# ISS_ISP5_SYS1 register map
Vendor: Texas Instruments
Registers are 32-bit, access not given, reset 0x0 unless marked. A register's access mark holds for its fields unless they carry their own. Offsets are as the file gives them; [hi:lo] are bit positions; {n}, {i} and the like mark numbered series.

## ISS_ISP5_SYS1 (part 2 of 2)
0x00 ISP5_REVISION ro reset not defined — IP Revision Identifier (X.Y.R) Used by software to track features, bugs, and compatibility
  [31:0] REVISION — IP Revision
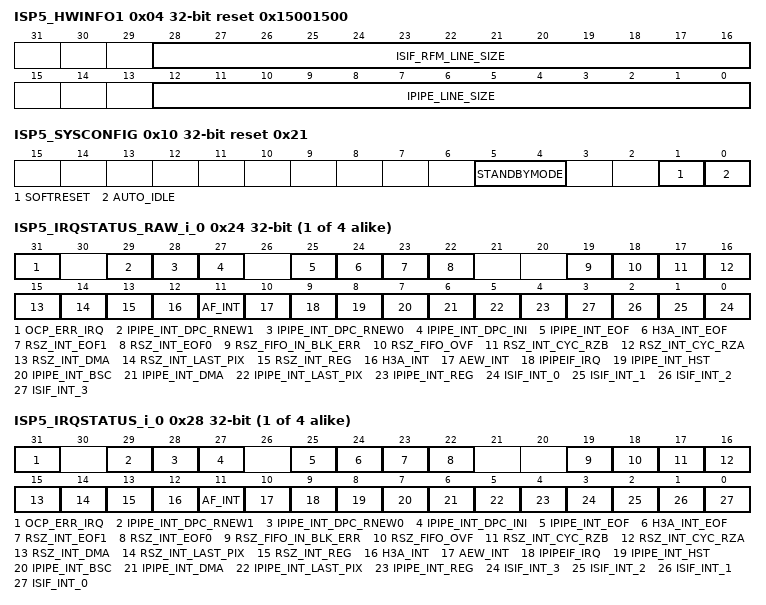
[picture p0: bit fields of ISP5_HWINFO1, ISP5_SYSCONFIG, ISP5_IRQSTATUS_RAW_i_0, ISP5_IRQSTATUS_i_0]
0x04 ISP5_HWINFO1 ro reset 0x15001500 — GENERIC PARAMETER REGISTER Information about the hardware configuration of the IP module.
  [28:16] ISIF_RFM_LINE_SIZE — Memory line size for the data reformatter in the ISIF module.
  [12:0] IPIPE_LINE_SIZE — Memory line size for the IPIPE module
0x08 ISP5_HWINFO2 ro reset 0xBC0 — GENERIC PARAMETER REGISTER Information about the hardware configuration of the IP module.
  [12:0] H3A_LINE_SIZE — Memory line size for the H3A module
0x10 ISP5_SYSCONFIG access per field reset 0x21 — Clock management configuration
  [5:4] STANDBYMODE rw — Configuration of the local initiator state management mode. By definition, initiator may generate read/write transaction as long as it is out of STANDBY state.
    0=Force-standby mode: local initiator is unconditionally placed in standby state. Backup mode, for debug only.; 1=No-standby mode: local initiator is unconditionally placed out of standby state. Backup mode, for debug only.; 2=Smart-standby mode: local initiator standby status depends on local conditions, that is, the module's functional requirement from the initiator. IP module must not generate (initiator-related) wake-up events. Generation of the MStandby signal must be initiated by the firmware by writing .MSTANDBY = 1.
  [1] SOFTRESET rw — Software reset. The soft reset will cause the MStandby to be asserted as the reset value of the ISP5_CTRL.MSTANDBY bit is 1. After a soft reset, the software must ensure not to perform any access for 16 clock cycles (OCP-slave port frequency) after writing this bit. The OCP slave port is running at half the frequency of the functional clock. Before issuing a soft reset, the software must ensure that no more traffic is being generated by the ISP. Basically, it means that the camera module must be stopped from sending data and/or that the ISP modules are disabled. The last interrupt triggered by the ISP design upon completion of the frame processing is rsz_int_dma. This rsz_int_dma event must be used to enable clean termination of the processing. The software must wait a few hundred cycles to trigger the soft reset after upon assertion of the rsz_int_dma, this is to ensure that the BL is completely drained. Software must set the ISP in standby mode before issuing the soft reset: Set ISP5_SYSCONFIG.STANDBYMODE = 2 (smart standby). Set ISP5_CTRL.MSTANDBY to 1. Poll for ISP5_CTRL.MSTANDBY_WAIT = 1. Then, the soft reset can be applied (ISP5_SYSCONFIG.SOFTRESET = 1).
    0=SOFTRESET_0_w (No action); 1=SOFTRESET_1_w (Initiate software reset); 1=SOFTRESET_1_r (Reset (software or other) ongoing); 0=SOFTRESET_0_r (Reset done, no pending action)
  [0] AUTO_IDLE ro — Auto clock gating. Always enabled.
{0x24+0x10*i} ISP5_IRQSTATUS_RAW_i_{i} (i=0..3) — Per-event raw interrupt status vector. Raw status is set even if event is not enabled. Write 1 to set the (raw) status, mostly for debug. The ISP outputs four interrupt lines, ISP_IRQ0 to ISP_IRQ3. Any internal ISP event can be merged on the four lines. A same event must be enabled on only one interrupt line.
  [31] OCP_ERR_IRQ — An OCP error has been received on the ISP master port. (access RW W1toSet)
    0=OCP_ERR_IRQ_0_w (No action); 1=OCP_ERR_IRQ_1_w (Set event (debug)); 1=OCP_ERR_IRQ_1_r (Event pending); 0=OCP_ERR_IRQ_0_r (No event pending)
  [29] IPIPE_INT_DPC_RNEW1 — (access RW W1toSet)
    0=IPIPE_INT_DPC_RNEW1_0_w (No action); 1=IPIPE_INT_DPC_RNEW1_1_w (Set event (debug)); 1=IPIPE_INT_DPC_RNEW1_1_r (Event pending); 0=IPIPE_INT_DPC_RNEW1_0_r (No event pending)
  [28] IPIPE_INT_DPC_RNEW0 — (access RW W1toSet)
    0=IPIPE_INT_DPC_RNEW0_0_w (No action); 1=IPIPE_INT_DPC_RNEW0_1_w (Set event (debug)); 1=IPIPE_INT_DPC_RNEW0_1_r (Event pending); 0=IPIPE_INT_DPC_RNEW0_0_r (No event pending)
  [27] IPIPE_INT_DPC_INI — (access RW W1toSet)
    0=IPIPE_INT_DPC_INI_0_w (No action); 1=IPIPE_INT_DPC_INI_1_w (Set event (debug)); 1=IPIPE_INT_DPC_INI_1_r (Event pending); 0=IPIPE_INT_DPC_INI_0_r (No event pending)
  [25] IPIPE_INT_EOF — (access RW W1toSet)
    0=IPIPE_INT_EOF_0_w (No action); 1=IPIPE_INT_EOF_1_w (Set event (debug)); 1=IPIPE_INT_EOF_1_r (Event pending); 0=IPIPE_INT_EOF_0_r (No event pending)
  [24] H3A_INT_EOF — (access RW W1toSet)
    0=H3A_INT_EOF_0_w (No action); 1=H3A_INT_EOF_1_w (Set event (debug)); 1=H3A_INT_EOF_1_r (Event pending); 0=H3A_INT_EOF_0_r (No event pending)
  [23] RSZ_INT_EOF1 — RESIZER module event: This event signals that the BL has received the EOF signal from the resizer B engine which happens one the last transfer in the frame has happened. Note that because the BL has FIFOs it may take some additional time before true data transfer completion to memory. (access RW W1toSet)
    0=RSZ_INT_EOF1_0_w (No action); 1=RSZ_INT_EOF1_1_w (Set event (debug)); 1=RSZ_INT_EOF1_1_r (Event pending); 0=RSZ_INT_EOF1_0_r (No event pending)
  [22] RSZ_INT_EOF0 — RESIZER module event: This event signals that the BL has received the EOF signal from the resizer A engine which happens one the last transfer in the frame has happened. Note that because the BL has FIFOs it may take some additional time before true data transfer completion to memory. (access RW W1toSet)
    0=RSZ_INT_EOF0_0_w (No action); 1=RSZ_INT_EOF0_1_w (Set event (debug)); 1=RSZ_INT_EOF0_1_r (Event pending); 0=RSZ_INT_EOF0_0_r (No event pending)
  [19] RSZ_FIFO_IN_BLK_ERR — This event signals that the minimum vertical blanking period has not been respected causing errors in the input data buffering submodule. This event will be triggered when the rsz_int_reg event of frame N is triggered before the rsz_int_dma of frame N + 1. This event would typically happen at the transition between two frames because there is not enough vertical blanking between frames: the firmware must take care to ensure enough vertical blanking. The hardware cannot recover from this error. It will be required to perform a reset of the IP. (access RW W1toSet)
    0=RSZ_FIFO_IN_BLK_ERR_0_w (No action); 1=RSZ_FIFO_IN_BLK_ERR_1_w (Set event (debug)); 1=RSZ_FIFO_IN_BLK_ERR_1_r (Event pending); 0=RSZ_FIFO_IN_BLK_ERR_0_r (No event pending)
  [18] RSZ_FIFO_OVF — This event signals that overflow happened in the input data buffering submodule. This event would typically happen while processing a frame because the video port pixel clock is too high: the firmware must take care to use a lower pixel clock at the input of the resizer module. Depending on the mode being used, the overflow can happen at different places: 1. Bypass mode: overflow happened in the input circular buffer. 2. Pass through mode: overflow happened on the module output interface (MTC) 3. Normal resize mode: overflow happened in the input circular buffer. The hardware cannot recover from this error. It will be required to perform a reset of the IP. (access RW W1toSet)
    0=RSZ_FIFO_OVF_0_w (No action); 1=RSZ_FIFO_OVF_1_w (Set event (debug)); 1=RSZ_FIFO_OVF_1_r (Event pending); 0=RSZ_FIFO_OVF_0_r (No event pending)
  [17] RSZ_INT_CYC_RZB — RESIZER module event: This event is the circular interrupt for RESIZER #B. An event can be triggered every time that RSZ_IRQ_RZB output lines have been written out to the RZB_SDR_Y buffer. The range can go from 1 to 8192 lines. Usually, this value should be such that the circular buffer vertical size (set by the RZB_SDR_Y_PTR_E register) is a multiple of RSZ_IRQ_RZB. Note that at the time the interrupt is triggered, the actual data write has not taken place. It may take a few hundred of cycles to complete the data write into system memory. This is not an issue since the start of the buffer is read first. (access RW W1toSet)
    0=RSZ_INT_CYC_RZB_0_w (No action); 1=RSZ_INT_CYC_RZB_1_w (Set event (debug)); 1=RSZ_INT_CYC_RZB_1_r (Event pending); 0=RSZ_INT_CYC_RZB_0_r (No event pending)
  [16] RSZ_INT_CYC_RZA — RESIZER module event: This event is the circular interrupt for RESIZER #A. An event can be triggered every time that RSZ_IRQ_RZA output lines have been written out to the RZA_SDR_Y buffer. The range can go from 1 to 8192 lines. Usually, the circular buffer vertical size (set by the RZA_SDR_Y_PTR_E register) should be a multiple of RSZ_IRQ_RZA. Note that at the time the interrupt is triggered, the actual data write has not taken place. It may take a few hundred of cycles to complete the data write into system memory. This is not an issue since the start of the buffer is read first. (access RW W1toSet)
    0=RSZ_INT_CYC_RZA_0_w (No action); 1=RSZ_INT_CYC_RZA_1_w (Set event (debug)); 1=RSZ_INT_CYC_RZA_1_r (Event pending); 0=RSZ_INT_CYC_RZA_0_r (No event pending)
  [15] RSZ_INT_DMA — This event is triggered when the last EOF (of the two MTC interfaces) is sent out to the BL and that the resizer core has returned to idle. rsz_int_dma is a true indication that all processing is finished for the particular frame on both resizer engines. (access RW W1toSet)
    0=RSZ_INT_DMA_0_w (No action); 1=RSZ_INT_DMA_1_w (Set event (debug)); 1=RSZ_INT_DMA_1_r (Event pending); 0=RSZ_INT_DMA_0_r (No event pending)
  [14] RSZ_INT_LAST_PIX — This event is triggered when the last pixel of the valid area is received. (access RW W1toSet)
    0=RSZ_INT_LAST_PIX_0_w (No action); 1=RSZ_INT_LAST_PIX_1_w (Set event (debug)); 1=RSZ_INT_LAST_PIX_1_r (Event pending); 0=RSZ_INT_LAST_PIX_0_r (No event pending)
  [13] RSZ_INT_REG — This event is triggered when the first pixel of the valid area is received. Shadowed registers can be updated at any time but the new value will take effect on the next rsz_int_reg event. (access RW W1toSet)
    0=RSZ_INT_REG_0_w (No action); 1=RSZ_INT_REG_1_w (Set event (debug)); 1=RSZ_INT_REG_1_r (Event pending); 0=RSZ_INT_REG_0_r (No event pending)
  [12] H3A_INT — (access RW W1toSet)
    0=H3A_INT_0_w (No action); 1=H3A_INT_1_w (Set event (debug)); 1=H3A_INT_1_r (Event pending); 0=H3A_INT_0_r (No event pending)
  [11] AF_INT — (access RW W1toSet)
    0=AF_INT_0_w (No action); 1=AF_INT_1_w (Set event (debug)); 1=AF_INT_1_r (Event pending); 0=AF_INT_0_r (No event pending)
  [10] AEW_INT — (access RW W1toSet)
    0=AEW_INT_0_w (No action); 1=AEW_INT_1_w (Set event (debug)); 1=AEW_INT_1_r (Event pending); 0=AEW_INT_0_r (No event pending)
  [9] IPIPEIF_IRQ — IPIPEIF module interrupt (access RW W1toSet)
    0=IPIPEIF_IRQ_0_w (No action); 1=IPIPEIF_IRQ_1_w (Set event (debug)); 1=IPIPEIF_IRQ_1_r (Event pending); 0=IPIPEIF_IRQ_0_r (No event pending)
  [8] IPIPE_INT_HST — (access RW W1toSet)
    0=IPIPE_INT_HST_0_w (No action); 1=IPIPE_INT_HST_1_w (Set event (debug)); 1=IPIPE_INT_HST_1_r (Event pending); 0=IPIPE_INT_HST_0_r (No event pending)
  [7] IPIPE_INT_BSC — (access RW W1toSet)
    0=IPIPE_INT_BSC_0_w (No action); 1=IPIPE_INT_BSC_1_w (Set event (debug)); 1=IPIPE_INT_BSC_1_r (Event pending); 0=IPIPE_INT_BSC_0_r (No event pending)
  [6] IPIPE_INT_DMA — (access RW W1toSet)
    0=IPIPE_INT_DMA_0_w (No action); 1=IPIPE_INT_DMA_1_w (Set event (debug)); 1=IPIPE_INT_DMA_1_r (Event pending); 0=IPIPE_INT_DMA_0_r (No event pending)
  [5] IPIPE_INT_LAST_PIX — (access RW W1toSet)
    0=IPIPE_INT_LAST_PIX_0_w (No action); 1=IPIPE_INT_LAST_PIX_1_w (Set event (debug)); 1=IPIPE_INT_LAST_PIX_1_r (Event pending); 0=IPIPE_INT_LAST_PIX_0_r (No event pending)
  [4] IPIPE_INT_REG — (access RW W1toSet)
    0=IPIPE_INT_REG_0_w (No action); 1=IPIPE_INT_REG_1_w (Set event (debug)); 1=IPIPE_INT_REG_1_r (Event pending); 0=IPIPE_INT_REG_0_r (No event pending)
  [n] ISIF_INT_{n} (n=0..3) — (access RW W1toSet)
    0=ISIF_INT_{n}_0_w (No action); 1=ISIF_INT_{n}_1_w (Set event (debug)); 1=ISIF_INT_{n}_1_r (Event pending); 0=ISIF_INT_{n}_0_r (No event pending)
{0x28+0x10*i} ISP5_IRQSTATUS_i_{i} (i=0..3) — Per-event 'enabled' interrupt status vector. Enabled status is not set unless event is enabled. Write 1 to clear the status after interrupt has been serviced (raw status gets cleared, that is, even if not enabled). The ISP outputs four interrupt lines, ISP_IRQ0 to ISP_IRQ3. Any internal ISP event can be merged on the four lines. A same event must be enabled on only one interrupt line.
  [31] OCP_ERR_IRQ — An OCP error has been received on the ISP master port. (access RW W1toClr)
    0=OCP_ERR_IRQ_0_w (No action); 1=OCP_ERR_IRQ_1_w (Clear (raw) event); 1=OCP_ERR_IRQ_1_r (Event pending); 0=OCP_ERR_IRQ_0_r (No (enabled) event pending)
  [29] IPIPE_INT_DPC_RNEW1 — (access RW W1toClr)
    0=IPIPE_INT_DPC_RNEW1_0_w (No action); 1=IPIPE_INT_DPC_RNEW1_1_w (Clear (raw) event); 1=IPIPE_INT_DPC_RNEW1_1_r (Event pending); 0=IPIPE_INT_DPC_RNEW1_0_r (No (enabled) event pending)
  [28] IPIPE_INT_DPC_RNEW0 — (access RW W1toClr)
    0=IPIPE_INT_DPC_RNEW0_0_w (No action); 1=IPIPE_INT_DPC_RNEW0_1_w (Clear (raw) event); 1=IPIPE_INT_DPC_RNEW0_1_r (Event pending); 0=IPIPE_INT_DPC_RNEW0_0_r (No (enabled) event pending)
  [27] IPIPE_INT_DPC_INI — (access RW W1toClr)
    0=IPIPE_INT_DPC_INI_0_w (No action); 1=IPIPE_INT_DPC_INI_1_w (Clear (raw) event); 1=IPIPE_INT_DPC_INI_1_r (Event pending); 0=IPIPE_INT_DPC_INI_0_r (No (enabled) event pending)
  [25] IPIPE_INT_EOF — (access RW W1toClr)
    0=IPIPE_INT_EOF_0_w (No action); 1=IPIPE_INT_EOF_1_w (Clear (raw) event); 1=IPIPE_INT_EOF_1_r (Event pending); 0=IPIPE_INT_EOF_0_r (No (enabled) event pending)
  [24] H3A_INT_EOF — (access RW W1toClr)
    0=H3A_INT_EOF_0_w (No action); 1=H3A_INT_EOF_1_w (Clear (raw) event); 1=H3A_INT_EOF_1_r (Event pending); 0=H3A_INT_EOF_0_r (No (enabled) event pending)
  [23] RSZ_INT_EOF1 — RESIZER module event: This event signals that the BL has received the EOF signal from the resizer B engine which happens one the last transfer in the frame has happened. Note that because the BL has FIFOs it may take some additional time before true data transfer completion to memory. (access RW W1toClr)
    0=RSZ_INT_EOF1_0_w (No action); 1=RSZ_INT_EOF1_1_w (Clear (raw) event); 1=RSZ_INT_EOF1_1_r (Event pending); 0=RSZ_INT_EOF1_0_r (No (enabled) event pending)
  [22] RSZ_INT_EOF0 — RESIZER module event: This event signals that the BL has received the EOF signal from the resizer A engine which happens one the last transfer in the frame has happened. Note that because the BL has FIFOs it may take some additional time before true data transfer completion to memory. (access RW W1toClr)
    0=RSZ_INT_EOF0_0_w (No action); 1=RSZ_INT_EOF0_1_w (Clear (raw) event); 1=RSZ_INT_EOF0_1_r (Event pending); 0=RSZ_INT_EOF0_0_r (No (enabled) event pending)
  [19] RSZ_FIFO_IN_BLK_ERR — This event signals that the minimum vertical blanking period has not been respected causing errors in the input data buffering submodule. This event will be triggered when the rsz_int_reg event of frame N is triggered before the rsz_int_dma of frame N + 1. This event would typically happen at the transition between two frames because there is not enough vertical blanking between frames: the firmware must take care to ensure enough vertical blanking. The hardware cannot recover from this error. It will be required to perform a reset of the IP. (access RW W1toClr)
    0=RSZ_FIFO_IN_BLK_ERR_0_w (No action); 1=RSZ_FIFO_IN_BLK_ERR_1_w (Clear (raw) event); 1=RSZ_FIFO_IN_BLK_ERR_1_r (Event pending); 0=RSZ_FIFO_IN_BLK_ERR_0_r (No (enabled) event pending)
  [18] RSZ_FIFO_OVF — This event signals that overflow happened in the input data buffering submodule or in the RSZ output interface. This event would typically happen while processing a frame because the video port pixel clock is too high: the firmware must take care to use a lower pixel clock at the input of the resizer module. The hardware cannot recover from this error. It will be required to perform a reset of the IP. (access RW W1toClr)
    0=RSZ_FIFO_OVF_0_w (No action); 1=RSZ_FIFO_OVF_1_w (Clear (raw) event); 1=RSZ_FIFO_OVF_1_r (Event pending); 0=RSZ_FIFO_OVF_0_r (No (enabled) event pending)
  [17] RSZ_INT_CYC_RZB — RESIZER module event: This event is the circular interrupt for RESIZER #B. An event can be triggered every time that RSZ_IRQ_RZB output lines have been written out to the RZB_SDR_Y buffer. The range can go from 1 to 8192 lines. Usually, this value should be such that the circular buffer vertical size (set by the RZB_SDR_Y_PTR_E register) is a multiple of RSZ_IRQ_RZB. Note that at the time the interrupt is triggered, the actual data write has not taken place. It may take a few hundred of cycles to complete the data write into system memory. This is not an issue since the start of the buffer is read first. (access RW W1toClr)
    0=RSZ_INT_CYC_RZB_0_w (No action); 1=RSZ_INT_CYC_RZB_1_w (Clear (raw) event); 1=RSZ_INT_CYC_RZB_1_r (Event pending); 0=RSZ_INT_CYC_RZB_0_r (No (enabled) event pending)
  [16] RSZ_INT_CYC_RZA — RESIZER module event: This event is the circular interrupt for RESIZER #A. An event can be triggered every time that RSZ_IRQ_RZA output lines have been written out to the RZA_SDR_Y buffer. The range can go from 1 to 8192 lines. Usually, the circular buffer vertical size (set by the RZA_SDR_Y_PTR_E register) should be a multiple of RSZ_IRQ_RZA. Note that at the time the interrupt is triggered, the actual data write has not taken place. It may take a few hundred of cycles to complete the data write into system memory. This is not an issue since the start of the buffer is read first. (access RW W1toClr)
    0=RSZ_INT_CYC_RZA_0_w (No action); 1=RSZ_INT_CYC_RZA_1_w (Clear (raw) event); 1=RSZ_INT_CYC_RZA_1_r (Event pending); 0=RSZ_INT_CYC_RZA_0_r (No (enabled) event pending)
  [15] RSZ_INT_DMA — This event is triggered when the last EOF (of the two MTC interfaces) is sent out to the BL and that the resizer core has returned to idle. rsz_int_dma is a true indication that all processing is finished for the particular frame on both resizer engines. (access RW W1toClr)
    0=RSZ_INT_DMA_0_w (No action); 1=RSZ_INT_DMA_1_w (Clear (raw) event); 1=RSZ_INT_DMA_1_r (Event pending); 0=RSZ_INT_DMA_0_r (No (enabled) event pending)
  [14] RSZ_INT_LAST_PIX — This event is triggered when the last pixel of the valid area is received. (access RW W1toClr)
    0=RSZ_INT_LAST_PIX_0_w (No action); 1=RSZ_INT_LAST_PIX_1_w (Clear (raw) event); 1=RSZ_INT_LAST_PIX_1_r (Event pending); 0=RSZ_INT_LAST_PIX_0_r (No (enabled) event pending)
  [13] RSZ_INT_REG — This event is triggered when the first pixel of the valid area is received. Shadowed registers can be updated at any time but the new value will take effect on the next rsz_int_reg event. (access RW W1toClr)
    0=RSZ_INT_REG_0_w (No action); 1=RSZ_INT_REG_1_w (Clear (raw) event); 1=RSZ_INT_REG_1_r (Event pending); 0=RSZ_INT_REG_0_r (No (enabled) event pending)
  [12] H3A_INT — (access RW W1toClr)
    0=H3A_INT_0_w (No action); 1=H3A_INT_1_w (Clear (raw) event); 1=H3A_INT_1_r (Event pending); 0=H3A_INT_0_r (No (enabled) event pending)
  [11] AF_INT — (access RW W1toClr)
    0=AF_INT_0_w (No action); 1=AF_INT_1_w (Clear (raw) event); 1=AF_INT_1_r (Event pending); 0=AF_INT_0_r (No (enabled) event pending)
  [10] AEW_INT — (access RW W1toClr)
    0=AEW_INT_0_w (No action); 1=AEW_INT_1_w (Clear (raw) event); 1=AEW_INT_1_r (Event pending); 0=AEW_INT_0_r (No (enabled) event pending)
  [9] IPIPEIF_IRQ — IPIPEIF module interrupt (access RW W1toClr)
    0=IPIPEIF_IRQ_0_w (No action); 1=IPIPEIF_IRQ_1_w (Clear (raw) event); 1=IPIPEIF_IRQ_1_r (Event pending); 0=IPIPEIF_IRQ_0_r (No (enabled) event pending)
  [8] IPIPE_INT_HST — (access RW W1toClr)
    0=IPIPE_INT_HST_0_w (No action); 1=IPIPE_INT_HST_1_w (Clear (raw) event); 1=IPIPE_INT_HST_1_r (Event pending); 0=IPIPE_INT_HST_0_r (No (enabled) event pending)
  [7] IPIPE_INT_BSC — (access RW W1toClr)
    0=IPIPE_INT_BSC_0_w (No action); 1=IPIPE_INT_BSC_1_w (Clear (raw) event); 1=IPIPE_INT_BSC_1_r (Event pending); 0=IPIPE_INT_BSC_0_r (No (enabled) event pending)
  [6] IPIPE_INT_DMA — (access RW W1toClr)
    0=IPIPE_INT_DMA_0_w (No action); 1=IPIPE_INT_DMA_1_w (Clear (raw) event); 1=IPIPE_INT_DMA_1_r (Event pending); 0=IPIPE_INT_DMA_0_r (No (enabled) event pending)
  [5] IPIPE_INT_LAST_PIX — (access RW W1toClr)
    0=IPIPE_INT_LAST_PIX_0_w (No action); 1=IPIPE_INT_LAST_PIX_1_w (Clear (raw) event); 1=IPIPE_INT_LAST_PIX_1_r (Event pending); 0=IPIPE_INT_LAST_PIX_0_r (No (enabled) event pending)
  [4] IPIPE_INT_REG — (access RW W1toClr)
    0=IPIPE_INT_REG_0_w (No action); 1=IPIPE_INT_REG_1_w (Clear (raw) event); 1=IPIPE_INT_REG_1_r (Event pending); 0=IPIPE_INT_REG_0_r (No (enabled) event pending)
  [3] ISIF_INT_3 — LSC interrupt issued by 2D-LSC block. Four types of 2D-LSC can be generated and mapped to the INT_3 line. For more information, see, (access RW W1toClr)
    0=ISIF_INT_3_0_w (No action); 1=ISIF_INT_3_1_w (Clear (raw) event); 1=ISIF_INT_3_1_r (Event pending); 0=ISIF_INT_3_0_r (No (enabled) event pending)
  [2] ISIF_INT_2 — VD interrupt 2 event. Read this bit to check the interrupt mapped to the INT_2 line. This interrupt is also set based on the VD pulse position after receiving a configured number of horizontal pulse signals. For more information, see, (access RW W1toClr)
    0=ISIF_INT_2_0_w (No action); 1=ISIF_INT_2_1_w (Clear (raw) event); 1=ISIF_INT_2_1_r (Event pending); 0=ISIF_INT_2_0_r (No (enabled) event pending)
  [1] ISIF_INT_1 — VD interrupt 1 event. Read this bit to check the interrupt mapped to the INT_1 line. This interrupt is also set based on the VD pulse position after receiving a configured number of horizontal pulse signals. For more information, see, (access RW W1toClr)
    0=ISIF_INT_1_0_w (No action); 1=ISIF_INT_1_1_w (Clear (raw) event); 1=ISIF_INT_1_1_r (Event pending); 0=ISIF_INT_1_0_r (No (enabled) event pending)
  [0] ISIF_INT_0 — VD interrupt 0 event. Read this bit to check the interrupt mapped to the INT_0 line. This interrupt is also set based on the VD pulse position after receiving a configured number of horizontal pulse signals. For more information, see, (access RW W1toClr)
    0=ISIF_INT_0_0_w (No action); 1=ISIF_INT_0_1_w (Clear (raw) event); 1=ISIF_INT_0_1_r (Event pending); 0=ISIF_INT_0_0_r (No (enabled) event pending)
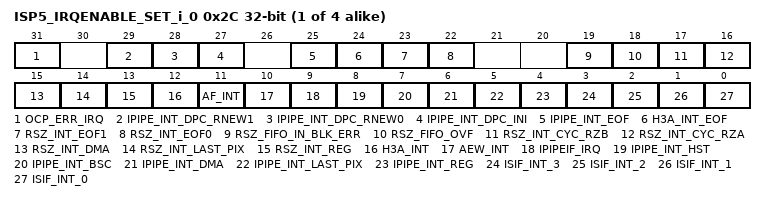
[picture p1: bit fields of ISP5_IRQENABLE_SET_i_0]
{0x2C+0x10*i} ISP5_IRQENABLE_SET_i_{i} (i=0..3) — Per-event interrupt enable bit vector. Write 1 to set (enable interrupt). Readout equal to corresponding _CLR register. The ISP outputs four interrupt lines, ISP_IRQ0 to ISP_IRQ3. Any internal ISP event can be merged on the four lines. A same event must be enabled on only one interrupt line.
  [31] OCP_ERR_IRQ — An OCP error has been received on the ISP master port. (access RW W1toSet)
    0=OCP_ERR_IRQ_0_w (No action); 1=OCP_ERR_IRQ_1_w (Enable interrupt); 1=OCP_ERR_IRQ_1_r (Interrupt enabled); 0=OCP_ERR_IRQ_0_r (Interrupt disabled (masked))
  [29] IPIPE_INT_DPC_RNEW1 — (access RW W1toSet)
    0=IPIPE_INT_DPC_RNEW1_0_w (No action); 1=IPIPE_INT_DPC_RNEW1_1_w (Enable interrupt); 1=IPIPE_INT_DPC_RNEW1_1_r (Interrupt enabled); 0=IPIPE_INT_DPC_RNEW1_0_r (Interrupt disabled (masked))
  [28] IPIPE_INT_DPC_RNEW0 — (access RW W1toSet)
    0=IPIPE_INT_DPC_RNEW0_0_w (No action); 1=IPIPE_INT_DPC_RNEW0_1_w (Enable interrupt); 1=IPIPE_INT_DPC_RNEW0_1_r (Interrupt enabled); 0=IPIPE_INT_DPC_RNEW0_0_r (Interrupt disabled (masked))
  [27] IPIPE_INT_DPC_INI — (access RW W1toSet)
    0=IPIPE_INT_DPC_INI_0_w (No action); 1=IPIPE_INT_DPC_INI_1_w (Enable interrupt); 1=IPIPE_INT_DPC_INI_1_r (Interrupt enabled); 0=IPIPE_INT_DPC_INI_0_r (Interrupt disabled (masked))
  [25] IPIPE_INT_EOF — (access RW W1toSet)
    0=IPIPE_INT_EOF_0_w (No action); 1=IPIPE_INT_EOF_1_w (Enable interrupt); 1=IPIPE_INT_EOF_1_r (Interrupt enabled); 0=IPIPE_INT_EOF_0_r (Interrupt disabled (masked))
  [24] H3A_INT_EOF — (access RW W1toSet)
    0=H3A_INT_EOF_0_w (No action); 1=H3A_INT_EOF_1_w (Enable interrupt); 1=H3A_INT_EOF_1_r (Interrupt enabled); 0=H3A_INT_EOF_0_r (Interrupt disabled (masked))
  [23] RSZ_INT_EOF1 — RESIZER module event: This event signals that the BL has received the EOF signal from the resizer B engine which happens one the last transfer in the frame has happened. Note that because the BL has FIFOs it may take some additional time before true data transfer completion to memory. (access RW W1toSet)
    0=RSZ_INT_EOF1_0_w (No action); 1=RSZ_INT_EOF1_1_w (Enable interrupt); 1=RSZ_INT_EOF1_1_r (Interrupt enabled); 0=RSZ_INT_EOF1_0_r (Interrupt disabled (masked))
  [22] RSZ_INT_EOF0 — RESIZER module event: This event signals that the BL has received the EOF signal from the resizer A engine which happens one the last transfer in the frame has happened. Note that because the BL has FIFOs it may take some additional time before true data transfer completion to memory. (access RW W1toSet)
    0=RSZ_INT_EOF0_0_w (No action); 1=RSZ_INT_EOF0_1_w (Enable interrupt); 1=RSZ_INT_EOF0_1_r (Interrupt enabled); 0=RSZ_INT_EOF0_0_r (Interrupt disabled (masked))
  [19] RSZ_FIFO_IN_BLK_ERR — This event signals that the minimum vertical blanking period has not been respected causing errors in the input data buffering submodule. This event will be triggered when the rsz_int_reg event of frame N is triggered before the rsz_int_dma of frame N + 1. This event would typically happen at the transition between two frames because there is not enough vertical blanking between frames: the firmware must take care to ensure enough vertical blanking. The hardware cannot recover from this error. It will be required to perform a reset of the IP. (access RW W1toSet)
    0=RSZ_FIFO_IN_BLK_ERR_0_w (No action); 1=RSZ_FIFO_IN_BLK_ERR_1_w (Enable interrupt); 1=RSZ_FIFO_IN_BLK_ERR_1_r (Interrupt enabled); 0=RSZ_FIFO_IN_BLK_ERR_0_r (Interrupt disabled (masked))
  [18] RSZ_FIFO_OVF — This event signals that overflow happened in the input data buffering submodule or in the RSZ output interface. This event would typically happen while processing a frame because the video port pixel clock is too high: the firmware must take care to use a lower pixel clock at the input of the resizer module. The hardware cannot recover from this error. It will be required to perform a reset of the IP. (access RW W1toSet)
    0=RSZ_FIFO_OVF_0_w (No action); 1=RSZ_FIFO_OVF_1_w (Enable interrupt); 1=RSZ_FIFO_OVF_1_r (Interrupt enabled); 0=RSZ_FIFO_OVF_0_r (Interrupt disabled (masked))
  [17] RSZ_INT_CYC_RZB — RESIZER module event: This event is the circular interrupt for RESIZER #B. An event can be triggered every time that RSZ_IRQ_RZB output lines have been written out to the RZB_SDR_Y buffer. The range can go from 1 to 8192 lines. Usually, this value should be such that the circular buffer vertical size (set by the RZB_SDR_Y_PTR_E register) is a multiple of RSZ_IRQ_RZB. Note that at the time the interrupt is triggered, the actual data write has not taken place. It may take a few hundred of cycles to complete the data write into system memory. This is not an issue since the start of the buffer is read first. (access RW W1toSet)
    0=RSZ_INT_CYC_RZB_0_w (No action); 1=RSZ_INT_CYC_RZB_1_w (Enable interrupt); 1=RSZ_INT_CYC_RZB_1_r (Interrupt enabled); 0=RSZ_INT_CYC_RZB_0_r (Interrupt disabled (masked))
  [16] RSZ_INT_CYC_RZA — RESIZER module event: This event is the circular interrupt for RESIZER #A. An event can be triggered every time that RSZ_IRQ_RZA output lines have been written out to the RZA_SDR_Y buffer. The range can go from 1 to 8192 lines. Usually, the circular buffer vertical size (set by the RZA_SDR_Y_PTR_E register) should be a multiple of RSZ_IRQ_RZA. Note that at the time the interrupt is triggered, the actual data write has not taken place. It may take a few hundred of cycles to complete the data write into system memory. This is not an issue since the start of the buffer is read first. (access RW W1toSet)
    0=RSZ_INT_CYC_RZA_0_w (No action); 1=RSZ_INT_CYC_RZA_1_w (Enable interrupt); 1=RSZ_INT_CYC_RZA_1_r (Interrupt enabled); 0=RSZ_INT_CYC_RZA_0_r (Interrupt disabled (masked))
  [15] RSZ_INT_DMA — This event is triggered when the last EOF (of the two MTC interfaces) is sent out to the BL and that the resizer core has returned to idle. rsz_int_dma is a true indication that all processing is finished for the particular frame on both resizer engines. (access RW W1toSet)
    0=RSZ_INT_DMA_0_w (No action); 1=RSZ_INT_DMA_1_w (Enable interrupt); 1=RSZ_INT_DMA_1_r (Interrupt enabled); 0=RSZ_INT_DMA_0_r (Interrupt disabled (masked))
  [14] RSZ_INT_LAST_PIX — This event is triggered when the last pixel of the valid area is received. (access RW W1toSet)
    0=RSZ_INT_LAST_PIX_0_w (No action); 1=RSZ_INT_LAST_PIX_1_w (Enable interrupt); 1=RSZ_INT_LAST_PIX_1_r (Interrupt enabled); 0=RSZ_INT_LAST_PIX_0_r (Interrupt disabled (masked))
  [13] RSZ_INT_REG — This event is triggered when the first pixel of the valid area is received. Shadowed registers can be updated at any time but the new value will take effect on the next rsz_int_reg event. (access RW W1toSet)
    0=RSZ_INT_REG_0_w (No action); 1=RSZ_INT_REG_1_w (Enable interrupt); 1=RSZ_INT_REG_1_r (Interrupt enabled); 0=RSZ_INT_REG_0_r (Interrupt disabled (masked))
  [12] H3A_INT — (access RW W1toSet)
    0=H3A_INT_0_w (No action); 1=H3A_INT_1_w (Enable interrupt); 1=H3A_INT_1_r (Interrupt enabled); 0=H3A_INT_0_r (Interrupt disabled (masked))
  [11] AF_INT — (access RW W1toSet)
    0=AF_INT_0_w (No action); 1=AF_INT_1_w (Enable interrupt); 1=AF_INT_1_r (Interrupt enabled); 0=AF_INT_0_r (Interrupt disabled (masked))
  [10] AEW_INT — (access RW W1toSet)
    0=AEW_INT_0_w (No action); 1=AEW_INT_1_w (Enable interrupt); 1=AEW_INT_1_r (Interrupt enabled); 0=AEW_INT_0_r (Interrupt disabled (masked))
  [9] IPIPEIF_IRQ — IPIPEIF module interrupt (access RW W1toSet)
    0=IPIPEIF_IRQ_0_w (No action); 1=IPIPEIF_IRQ_1_w (Enable interrupt); 1=IPIPEIF_IRQ_1_r (Interrupt enabled); 0=IPIPEIF_IRQ_0_r (Interrupt disabled (masked))
  [8] IPIPE_INT_HST — (access RW W1toSet)
    0=IPIPE_INT_HST_0_w (No action); 1=IPIPE_INT_HST_1_w (Enable interrupt); 1=IPIPE_INT_HST_1_r (Interrupt enabled); 0=IPIPE_INT_HST_0_r (Interrupt disabled (masked))
  [7] IPIPE_INT_BSC — (access RW W1toSet)
    0=IPIPE_INT_BSC_0_w (No action); 1=IPIPE_INT_BSC_1_w (Enable interrupt); 1=IPIPE_INT_BSC_1_r (Interrupt enabled); 0=IPIPE_INT_BSC_0_r (Interrupt disabled (masked))
  [6] IPIPE_INT_DMA — (access RW W1toSet)
    0=IPIPE_INT_DMA_0_w (No action); 1=IPIPE_INT_DMA_1_w (Enable interrupt); 1=IPIPE_INT_DMA_1_r (Interrupt enabled); 0=IPIPE_INT_DMA_0_r (Interrupt disabled (masked))
  [5] IPIPE_INT_LAST_PIX — (access RW W1toSet)
    0=IPIPE_INT_LAST_PIX_0_w (No action); 1=IPIPE_INT_LAST_PIX_1_w (Enable interrupt); 1=IPIPE_INT_LAST_PIX_1_r (Interrupt enabled); 0=IPIPE_INT_LAST_PIX_0_r (Interrupt disabled (masked))
  [4] IPIPE_INT_REG — (access RW W1toSet)
    0=IPIPE_INT_REG_0_w (No action); 1=IPIPE_INT_REG_1_w (Enable interrupt); 1=IPIPE_INT_REG_1_r (Interrupt enabled); 0=IPIPE_INT_REG_0_r (Interrupt disabled (masked))
  [3] ISIF_INT_3 — LSC interrupt issued by the 2D-LSC block. Four types of 2D-LSC can be generated and mapped to the INT_3 line. For more information, see, (access RW W1toSet)
    0=ISIF_INT_3_0_w (No action); 1=ISIF_INT_3_1_w (Enable interrupt); 1=ISIF_INT_3_1_r (Interrupt enabled); 0=ISIF_INT_3_0_r (Interrupt disabled (masked))
  [2] ISIF_INT_2 — VD interrupt 2 event. Set this bit to enable the interrupt and map it to the INT_2 line. This interrupt is set based on the VD pulse position after receiving a configured number of horizontal pulse signals. For more information, see, (access RW W1toSet)
    0=ISIF_INT_2_0_w (No action); 1=ISIF_INT_2_1_w (Enable interrupt); 1=ISIF_INT_2_1_r (Interrupt enabled); 0=ISIF_INT_2_0_r (Interrupt disabled (masked))
  [1] ISIF_INT_1 — VD interrupt 1 event. Set this bit to enable the interrupt and map it to the INT_1 line. This interrupt is set based on the VD pulse position after receiving a configured number of horizontal pulse signals. For more information, see, (access RW W1toSet)
    0=ISIF_INT_1_0_w (No action); 1=ISIF_INT_1_1_w (Enable interrupt); 1=ISIF_INT_1_1_r (Interrupt enabled); 0=ISIF_INT_1_0_r (Interrupt disabled (masked))
  [0] ISIF_INT_0 — VD interrupt 0 event. Set this bit to enable the interrupt mapped to INT_0 line. This interrupt is set based on the VD pulse position after receiving a configured number of horizontal pulse signals. For more information, see, (access RW W1toSet)
    0=ISIF_INT_0_0_w (No action); 1=ISIF_INT_0_1_w (Enable interrupt); 1=ISIF_INT_0_1_r (Interrupt enabled); 0=ISIF_INT_0_0_r (Interrupt disabled (masked))
